# CY8C5888LTQ_LP097 register map
File version: 0.1
CY8C58LP
Registers are 8-bit, read-write, no defined reset value unless marked. A register's access mark holds for its fields unless they carry their own. Offsets are from the block's base; lines under a group give offsets from that group; [hi:lo] are bit positions; {n}, {i} and the like mark numbered series; 'fields as' and 'values as' point back to an identical list; <NAME> marks a mode.

## Memory map
0x00000000 Timer_1
0x00000000 Opamp_1
0x00000000 Counter_1
0x00000000 Counter_2
0x00000000 PWM_1
0x00000000 ADC_SAR_Seq_1_SAR — SAR ADC
0x00000000 USBUART_1 — USBFS
0x00000000 Comp_1
0x00000000 ADC_SAR_1 — SAR ADC
0x00000000 VDAC8_1
0x40006461 Status_Reg_1
0x40006471 Control_Reg_1

## Timer_1
Base 0x00000000
0x40006402 Timer_1_COUNTER 16-bit — UDB.A0 - Current Down Counter Value
0x40006422 Timer_1_PERIOD 16-bit — UDB.D0 - Assigned Period
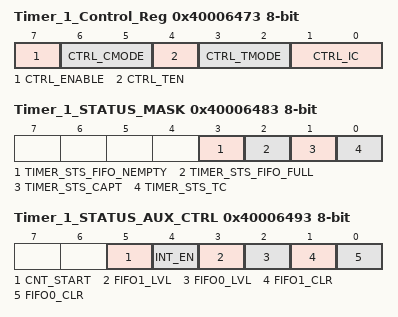
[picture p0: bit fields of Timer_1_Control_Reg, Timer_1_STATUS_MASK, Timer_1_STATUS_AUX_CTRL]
0x40006473 Timer_1_Control_Reg — UDB Control Register - Assigned Control Register Value
  [7] CTRL_ENABLE — Enable the Timer
  [6:5] CTRL_CMODE — Capture Mode
  [4] CTRL_TEN — Trigger Enable Bit
  [3:2] CTRL_TMODE — Trigger Mode
  [1:0] CTRL_IC — Interrupt Count
0x40006483 Timer_1_STATUS_MASK — UDB Status bits Interrupt Mask Enable Register
  [3] TIMER_STS_FIFO_NEMPTY ro — FIFO Empty status
  [2] TIMER_STS_FIFO_FULL ro — FIFO Full Status
  [1] TIMER_STS_CAPT ro — Enables the Interrupt on Capture
  [0] TIMER_STS_TC ro — Enables the Interrupt on TC
0x40006493 Timer_1_STATUS_AUX_CTRL — UDB Auxilliary Control Register
  [5] CNT_START — FIFO0 clear
    0=E_CNT_START0 (Disable counter); 1=E_CNT_START1 (Enable counter)
  [4] INT_EN
    0=E_INT_EN0 (Interrupt disabled); 1=E_INT_EN1 (Interrupt enabled)
  [3] FIFO1_LVL — FIFO level
    0=E_FIFO_LVL_0 (FIFO LVL: input mode: FIFO not full; output mode: FIFO not empty); 1=E_FIFO_LVL_1 (FIFO LVL: input mode: FIFO at least 1/2 empty; output mode: FIFO at least 1/2 full)
  [2] FIFO0_LVL — FIFO level
    values as FIFO1_LVL
  [1] FIFO1_CLR — FIFO1 clear
    0=E_FIFO_CLR_0 (Normal FIFO operation); 1=E_FIFO_CLR_1 (Clear FIFO state)
  [0] FIFO0_CLR — FIFO0 clear
    values as FIFO1_CLR

## Opamp_1
Base 0x00000000
0x400043A4 PM_ACT_CFG4 — Active Power Mode Configuration Register 4
  [3:0] EN_OPAMP — Enables subsystems during active power mode
    0=Blk_0 (Enables analog linear output buffer for Opamp block 0); 2=Blk_1 (Enables analog linear output buffer for Opamp block 1); 4=Blk_2 (Enables analog linear output buffer for Opamp block 2); 8=Blk_3 (Enables analog linear output buffer for Opamp block 3)
0x400043B4 PM_STBY_CFG4 — Standby Power Mode Configuration Register 4
  [3:0] EN_OPAMP — Enables subsystems during standby power mode
    values as PM_ACT_CFG4.EN_OPAMP
0x40004626 OPAMP__TR0 — Analog Output Buffer Trim Register 0
  [4:0] offset_trim — Offset Trim: 420uV typical step size; +/- 6.8mV offset trimmable range
0x40004627 OPAMP__TR1 — Analog Output Buffer Trim Register 1
0x4000585E OPAMP__CR — Analog Output Buffer Configuration Register
  [1:0] pwr_mode — Power Mode
    0=Default_Fast (Default Power mode Fast); 1=Slow (Power Mode Slow); 2=Medium (Power Mode Medium); 3=Fast (Power Mode Fast)
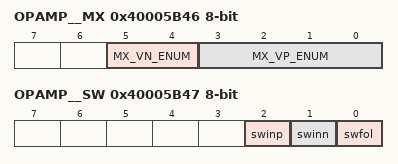
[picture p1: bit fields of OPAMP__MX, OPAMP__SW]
0x40005B46 OPAMP__MX — Analog Buffer Input Selection Register
  [5:4] MX_VN_ENUM — MUX select VN (Negative terminal input)
    0=OPAMP0_MX_VN_DEFAULT (Default - Not Connected (NC)); 1=OPAMP0_MX_VN_AG4 (MUX Selection AGL(4)); 2=OPAMP0_MX_VN_AG6 (MUX Selection AGL(6)); 3=OPAMP0_MX_VN_0x3 (Reserved (NC))
  [3:0] MX_VP_ENUM — MUX select VP (Positive terminal input)
    0=OPAMP0_MX_VP_DEFAULT (Default - Not Connected (NC)); {v}=OPAMP0_MX_VP_AG{v+3} (MUX Selection AGL({v+3})) (v=1..4); {v}=OPAMP0_MX_VP_ABUS{v-5} (MUX Selection ABUSL({v-5})) (v=5..8); 9=OPAMP0_MX_VP_VREF (MUX Selection: OPAMP Voltage Reference); {v}=OPAMP0_MX_VP_H_{0x0+v} (Reserved (NC)) (v=10..15)
0x40005B47 OPAMP__SW — Analog Buffer Routing Switch Register
  [2] swinp — Switch Enable Positive Input
  [1] swinn — Switch Enable Negative Input
  [0] swfol — Switch Enable Follow
